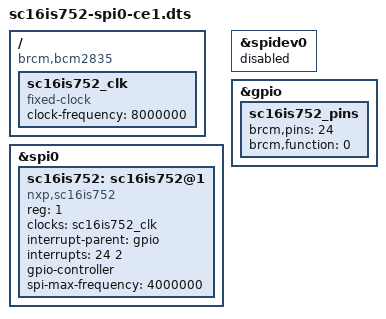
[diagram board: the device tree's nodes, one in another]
/dts-v1/;
/plugin/;

/ {
    compatible = "brcm,bcm2835";

    fragment@0 {
        target = <&spi0>;
        __overlay__ {
            status = "okay";
        };
    };

    fragment@1 {
        target = <&spidev0>;
        __overlay__ {
            status = "disabled";
        };
    };

    fragment@2 {
        target = <&gpio>;
        __overlay__ {
            sc16is752_pins: sc16is752_pins {
                brcm,pins = <24>;
                brcm,function = <0>; /* input */
            };
        };
    };

    fragment@3 {
        target = <&spi0>;
        __overlay__ {
            #address-cells = <1>;
            #size-cells = <0>;

            sc16is752: sc16is752@1 {
                compatible = "nxp,sc16is752";
                reg = <1>; /* CE1 */
                clocks = <&sc16is752_clk>;
                interrupt-parent = <&gpio>;
                interrupts = <24 2>; /* IRQ_TYPE_EDGE_FALLING */
                gpio-controller;
                #gpio-cells = <2>;
                spi-max-frequency = <4000000>;
            };
        };
    };

    fragment@4 {
        target-path = "/";
        __overlay__ {
            sc16is752_clk: sc16is752_clk {
                compatible = "fixed-clock";
                #clock-cells = <0>;
                clock-frequency = <8000000>;
            };
        };
    };

    __overrides__ {
        int_pin = <&sc16is752>, "interrupts:0",
                  <&sc16is752_pins>, "brcm,pins:0";
        xtal = <&sc16is752_clk>, "clock-frequency:0";
    };
};
